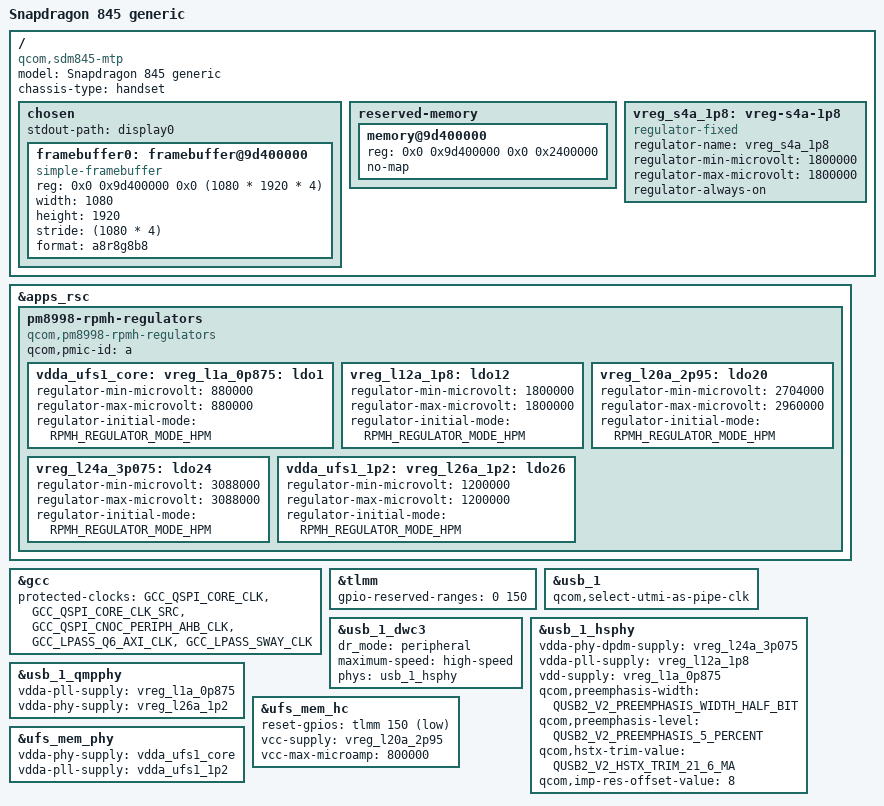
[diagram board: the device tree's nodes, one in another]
// SPDX-License-Identifier: BSD-3-Clause
/*
 * Copyright (c) 2022, Xilin Wu <strongtz@yeah.net>
 */

/dts-v1/;

#include <dt-bindings/gpio/gpio.h>
#include <dt-bindings/regulator/qcom,rpmh-regulator.h>

#include "sdm845.dtsi"
#include "pm8998.dtsi"

/ {
	model = "Snapdragon 845 generic";
	compatible = "qcom,sdm845-mtp", "qcom,sdm845";
	chassis-type = "handset";

	chosen {
		#address-cells = <2>;
		#size-cells = <2>;
		ranges;

		stdout-path = "display0";

		/* Use framebuffer setup by the bootloader. */
		framebuffer0: framebuffer@9d400000 {
			compatible = "simple-framebuffer";
			reg = <0x0 0x9d400000 0x0 (1080 * 1920 * 4)>;
			width = <1080>;
			height = <1920>;
			stride = <(1080 * 4)>;
			format = "a8r8g8b8";
		};
	};


	reserved-memory {
		/* Framebuffer region */
		memory@9d400000 {
			reg = <0x0 0x9d400000 0x0 0x2400000>;
			no-map;
		};
	};

	vreg_s4a_1p8: vreg-s4a-1p8 {
		compatible = "regulator-fixed";
		regulator-name = "vreg_s4a_1p8";

		regulator-min-microvolt = <1800000>;
		regulator-max-microvolt = <1800000>;
		regulator-always-on;
	};
};


&apps_rsc {
	pm8998-rpmh-regulators {
		compatible = "qcom,pm8998-rpmh-regulators";
		qcom,pmic-id = "a";

		vdda_ufs1_core:
		vreg_l1a_0p875: ldo1 {
			regulator-min-microvolt = <880000>;
			regulator-max-microvolt = <880000>;
			regulator-initial-mode = <RPMH_REGULATOR_MODE_HPM>;
		};

		vreg_l12a_1p8: ldo12 {
			regulator-min-microvolt = <1800000>;
			regulator-max-microvolt = <1800000>;
			regulator-initial-mode = <RPMH_REGULATOR_MODE_HPM>;
		};

		vreg_l20a_2p95: ldo20 {
			regulator-min-microvolt = <2704000>;
			regulator-max-microvolt = <2960000>;
			regulator-initial-mode = <RPMH_REGULATOR_MODE_HPM>;
		};

		vreg_l24a_3p075: ldo24 {
			regulator-min-microvolt = <3088000>;
			regulator-max-microvolt = <3088000>;
			regulator-initial-mode = <RPMH_REGULATOR_MODE_HPM>;
		};

		vdda_ufs1_1p2:
		vreg_l26a_1p2: ldo26 {
			regulator-min-microvolt = <1200000>;
			regulator-max-microvolt = <1200000>;
			regulator-initial-mode = <RPMH_REGULATOR_MODE_HPM>;
		};
	};
};

&gcc {
	protected-clocks = <GCC_QSPI_CORE_CLK>,
				<GCC_QSPI_CORE_CLK_SRC>,
				<GCC_QSPI_CNOC_PERIPH_AHB_CLK>,
				<GCC_LPASS_Q6_AXI_CLK>,
				<GCC_LPASS_SWAY_CLK>;
};

&tlmm {
	gpio-reserved-ranges = <0 150>;
};

&usb_1 {
	/* We'll use this as USB 2.0 only */
	qcom,select-utmi-as-pipe-clk;
	status = "okay";
};

&usb_1_dwc3 {
	dr_mode = "peripheral";

	/* Fastest mode for USB 2 */
	maximum-speed = "high-speed";

	/* Remove USB3 phy */
	phys = <&usb_1_hsphy>;
	phy-names = "usb2-phy";
};

&usb_1_hsphy {
	vdda-phy-dpdm-supply = <&vreg_l24a_3p075>;
	vdda-pll-supply = <&vreg_l12a_1p8>;
	vdd-supply = <&vreg_l1a_0p875>;

	qcom,preemphasis-width = <QUSB2_V2_PREEMPHASIS_WIDTH_HALF_BIT>;
	qcom,preemphasis-level = <QUSB2_V2_PREEMPHASIS_5_PERCENT>;
	qcom,hstx-trim-value = <QUSB2_V2_HSTX_TRIM_21_6_MA>;
	qcom,imp-res-offset-value = <8>;

	status = "okay";
};

&usb_1_qmpphy {
	vdda-pll-supply = <&vreg_l1a_0p875>;
	vdda-phy-supply = <&vreg_l26a_1p2>;
	status = "okay";
};

&ufs_mem_hc {
	reset-gpios = <&tlmm 150 GPIO_ACTIVE_LOW>;
	vcc-supply = <&vreg_l20a_2p95>;
	vcc-max-microamp = <800000>;
	status = "okay";
};

&ufs_mem_phy {
	vdda-phy-supply = <&vdda_ufs1_core>;
	vdda-pll-supply = <&vdda_ufs1_1p2>;
	status = "okay";
};
